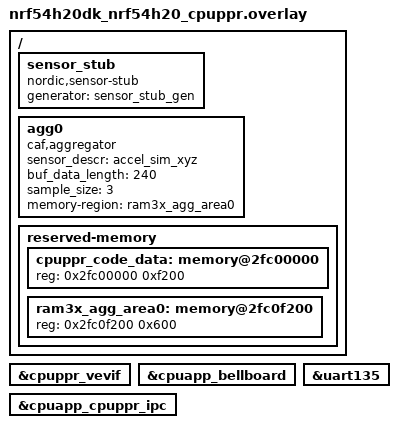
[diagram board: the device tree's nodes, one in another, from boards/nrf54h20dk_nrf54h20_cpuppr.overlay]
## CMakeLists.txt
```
#
# Copyright (c) 2022 Nordic Semiconductor ASA
#
# SPDX-License-Identifier: LicenseRef-Nordic-5-Clause
#

cmake_minimum_required(VERSION 3.20.0)

find_package(Zephyr REQUIRED HINTS $ENV{ZEPHYR_BASE})
project(remote)

#Include application application event headers
zephyr_library_include_directories(../src/events)

target_sources(app PRIVATE src/main.c)

# Add include directory for board specific CAF def files
zephyr_include_directories(
  ../configuration/
  ../configuration/${NORMALIZED_BOARD_TARGET}
)

add_subdirectory(../src/modules "${CMAKE_CURRENT_BINARY_DIR}/modules")
```

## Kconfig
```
#
# Copyright (c) 2022 Nordic Semiconductor ASA
#
# SPDX-License-Identifier: LicenseRef-Nordic-5-Clause
#

menu "Sensor manager sample (remote core)"
rsource "../src/modules/Kconfig"
endmenu

menu "Zephyr Kernel"
source "Kconfig.zephyr"
endmenu
```

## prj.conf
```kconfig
#
# Copyright (c) 2022 Nordic Semiconductor ASA
#
# SPDX-License-Identifier: LicenseRef-Nordic-5-Clause
#
################################################################################
# Application configuration

CONFIG_CAF=y

CONFIG_CAF_INIT_LOG_SENSOR_EVENTS=n

CONFIG_CAF_SENSOR_MANAGER=y

CONFIG_APP_EVENT_MANAGER=y
CONFIG_EVENT_MANAGER_PROXY=y
CONFIG_HEAP_MEM_POOL_SIZE=4096
CONFIG_REBOOT=y

CONFIG_SENSOR=y

CONFIG_IPC_SERVICE=y
CONFIG_MBOX=y

CONFIG_OPENAMP=y
CONFIG_OPENAMP_MASTER=n

################################################################################
# Debug configuration

CONFIG_ASSERT=y
CONFIG_RESET_ON_FATAL_ERROR=n

# Disable GPIO
CONFIG_GPIO=n

CONFIG_LOG=y
CONFIG_LOG_MODE_DEFERRED=y
```

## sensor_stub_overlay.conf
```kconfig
#
# Copyright (c) 2022 Nordic Semiconductor ASA
#
# SPDX-License-Identifier: LicenseRef-Nordic-5-Clause
#
################################################################################
# Application configuration overlay to select Sensor Stub

# Select Sensor Stub
CONFIG_SENSOR_SIM=n
CONFIG_SENSOR_STUB=y
```

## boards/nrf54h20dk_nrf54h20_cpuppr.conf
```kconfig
#
# Copyright (c) 2024 Nordic Semiconductor ASA
#
# SPDX-License-Identifier: LicenseRef-Nordic-5-Clause
#
################################################################################

CONFIG_ASSERT=n
CONFIG_BOOT_BANNER=n
CONFIG_HEAP_MEM_POOL_SIZE=512
CONFIG_SIZE_OPTIMIZATIONS=y

CONFIG_NCS_BOOT_BANNER=n

CONFIG_LOG_MODE_MINIMAL=y

CONFIG_CAF_INIT_LOG_SENSOR_EVENTS=y
```

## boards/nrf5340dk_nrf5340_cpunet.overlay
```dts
/*
 * Copyright (c) 2022 Nordic Semiconductor ASA
 *
 * SPDX-License-Identifier: LicenseRef-Nordic-5-Clause
 */

/ {
	reserved-memory {
		#address-cells = <1>;
		#size-cells = <1>;
		ranges;

		sram0_aggregator_area0: memory@2007f000 {
			reg = <0x2007f000 0x1000>;
		};
	};

	sensor_stub: sensor_stub {
		compatible = "nordic,sensor-stub";
		generator = "sensor_stub_gen";
		status = "okay";
	};

	agg0: agg0 {
		compatible = "caf,aggregator";
		sensor_descr = "accel_sim_xyz";
		buf_data_length = <240>;
		sample_size = <3>;
		memory-region = <&sram0_aggregator_area0>;
		status = "okay";
	};
};
```

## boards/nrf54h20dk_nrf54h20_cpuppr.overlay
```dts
/*
 * Copyright (c) 2024 Nordic Semiconductor ASA
 *
 * SPDX-License-Identifier: LicenseRef-Nordic-5-Clause
 */

/ {
	sensor_stub: sensor_stub {
		compatible = "nordic,sensor-stub";
		generator = "sensor_stub_gen";
		status = "okay";
	};

	agg0: agg0 {
		compatible = "caf,aggregator";
		sensor_descr = "accel_sim_xyz";
		buf_data_length = <240>;
		sample_size = <3>;
		memory-region = <&ram3x_agg_area0>;
	};

	reserved-memory {
		/* Place aggregator buffers in PPR memory region. */
		cpuppr_code_data: memory@2fc00000 {
			reg = <0x2fc00000 0xf200>;
		};

		ram3x_agg_area0: memory@2fc0f200 {
			reg = <0x2fc0f200 0x600>;
		};
	};
};

/* Enabled nodes required by IPC
 * Two mboxes, one for each sides and one ipc instance
 */

&cpuppr_vevif {
	status = "okay";
};

&cpuapp_bellboard {
	status = "okay";
};

&uart135 {
	/delete-property/ hw-flow-control;
};

ipc0: &cpuapp_cpuppr_ipc {
	status = "okay";
};
```

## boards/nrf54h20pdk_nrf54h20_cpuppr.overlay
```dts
/*
 * Copyright (c) 2024 Nordic Semiconductor ASA
 *
 * SPDX-License-Identifier: LicenseRef-Nordic-5-Clause
 */

 / {
	chosen {
		zephyr,sram = &cpuppr_code_data;
	};

	sensor_stub: sensor_stub {
		compatible = "nordic,sensor-stub";
		generator = "sensor_stub_gen";
		status = "okay";
	};

	agg0: agg0 {
		compatible = "caf,aggregator";
		sensor_descr = "accel_sim_xyz";
		buf_data_length = <240>;
		sample_size = <3>;
		memory-region = <&ram3x_agg_area0>;
	};
};

/* Place aggregator buffers in PPR memory region. */

&cpuppr_ram3x_region {
	#address-cells = <1>;
	#size-cells = <1>;
	ranges = <0x0 0x2fc00000 0x7000>;

	cpuppr_code_data: memory@0 {
		reg = <0x0 0x6a00>;
	};

	ram3x_agg_area0: memory@6a00 {
		reg = <0x6a00 0x600>;
	};
};

/* Enabled nodes required by IPC
 * Two mboxes, one for each sides and one ipc instance
 */

&cpuppr_vevif {
	status = "okay";
};

&cpuapp_bellboard {
	status = "okay";
};

ipc0: &cpuapp_cpuppr_ipc {
	status = "okay";
};
```

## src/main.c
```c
/*
 * Copyright (c) 2022 Nordic Semiconductor ASA
 *
 * SPDX-License-Identifier: LicenseRef-Nordic-5-Clause
 */

#include <zephyr/kernel.h>
#include <app_event_manager.h>

#define MODULE main

#include <caf/events/module_state_event.h>
#include <zephyr/logging/log.h>
#include <event_proxy_init.h>

LOG_MODULE_REGISTER(MODULE);

int main(void)
{
	int ret;

	LOG_INF("Event Manager Proxy remote_core started\n");

	ret = app_event_manager_init();
	if (ret) {
		LOG_ERR("Event Manager not initialized, err: %d", ret);
		__ASSERT_NO_MSG(false);
		return 0;
	}
	LOG_INF("Event manager initialized");

	ret = init_event_proxy("sensor_data_aggregator_release_buffer_event");
	if (ret) {
		LOG_ERR("Event Manager Proxy not initialized, err: %d", ret);
		__ASSERT_NO_MSG(false);
		return 0;
	}

	module_set_state(MODULE_STATE_READY);

	return 0;
}
```
